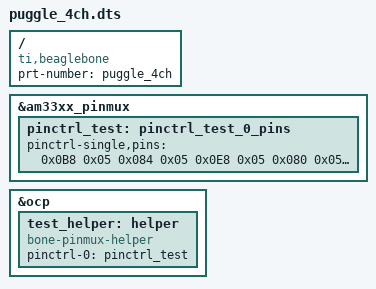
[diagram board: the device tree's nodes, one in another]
/dts-v1/;
/plugin/;
/ { compatible = "ti,beaglebone", "ti,beaglebone-black";

/* identification */
prt-number = "puggle_4ch";
fragment@0 {
target = <&am33xx_pinmux>;
__overlay__ {
pinctrl_test: pinctrl_test_0_pins {
pinctrl-single,pins = <
0x0B8 0x05 /* P8_39 LCD_DATA6, OUTPUT | MODE5 */
0x084 0x05 /* P8_20 GPMC_CSn2, OUTPUT | MODE5 */
0x0E8 0x05 /* P8_28 LCD_PCLK, OUTPUT | MODE5 */
0x080 0x05 /* P8_21 GPMC_CSn1, OUTPUT | MODE5 */
0x0E4 0x05 /* P8_29 LCD_HSYNC, OUTPUT | MODE5 */
0x0EC 0x06 /* P8_30 LCD_AC_BIAS_EN, INPUT | MODE6 */
>;
};
};
};

fragment@1 {
target = <&ocp>;
__overlay__ {
test_helper: helper {
compatible = "bone-pinmux-helper";
pinctrl-names = "default";
pinctrl-0 = <&pinctrl_test>;
status = "okay";
};
};
};
};
